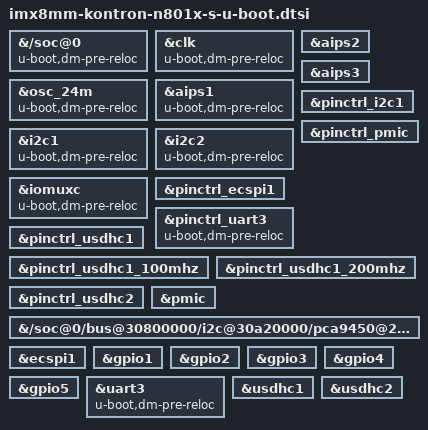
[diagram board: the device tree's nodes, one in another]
// SPDX-License-Identifier: GPL-2.0+
/*
 * Copyright (C) 2019 Kontron Electronics GmbH
 */

&{/soc@0} {
	u-boot,dm-pre-reloc;
	u-boot,dm-spl;
};

&clk {
	u-boot,dm-spl;
	u-boot,dm-pre-reloc;
};

&osc_24m {
	u-boot,dm-spl;
	u-boot,dm-pre-reloc;
};

&aips1 {
	u-boot,dm-spl;
	u-boot,dm-pre-reloc;
};

&aips2 {
	u-boot,dm-spl;
};

&aips3 {
	u-boot,dm-spl;
};

&i2c1 {
	u-boot,dm-spl;
	u-boot,dm-pre-reloc;
};

&i2c2 {
	status = "okay";
	u-boot,dm-spl;
	u-boot,dm-pre-reloc;
};

&iomuxc {
	u-boot,dm-spl;
	u-boot,dm-pre-reloc;
};

&pinctrl_ecspi1 {
	u-boot,dm-spl;
};

&pinctrl_i2c1 {
	u-boot,dm-spl;
};

&pinctrl_pmic {
	u-boot,dm-spl;
};

&pinctrl_uart3 {
	u-boot,dm-spl;
	u-boot,dm-pre-reloc;
};

&pinctrl_usdhc1 {
	u-boot,dm-spl;
};

&pinctrl_usdhc1_100mhz {
	u-boot,dm-spl;
};

&pinctrl_usdhc1_200mhz {
	u-boot,dm-spl;
};

&pinctrl_usdhc2 {
	u-boot,dm-spl;
};

&pmic {
	u-boot,dm-spl;
};

&{/soc@0/bus@30800000/i2c@30a20000/pca9450@25/regulators} {
	u-boot,dm-spl;
};

&ecspi1 {
	u-boot,dm-spl;
};

&gpio1 {
	u-boot,dm-spl;
};

&gpio2 {
	u-boot,dm-spl;
};

&gpio3 {
	u-boot,dm-spl;
};

&gpio4 {
	u-boot,dm-spl;
};

&gpio5 {
	u-boot,dm-spl;
};

&uart3 {
	u-boot,dm-spl;
	u-boot,dm-pre-reloc;
};

&usdhc1 {
	u-boot,dm-spl;
	/*
	 * U-Boot disables UHS support because it can not power cycle the MMC
	 * (regulator is always on). This results in an error message, when
	 * it tries to switch voltage on the card (esdhc_set_voltage error -5).
	 * For now we just remove the regulator to avoid this problem.
	 */
	/delete-property/ vqmmc-supply;
};

&usdhc2 {
	u-boot,dm-spl;
};
